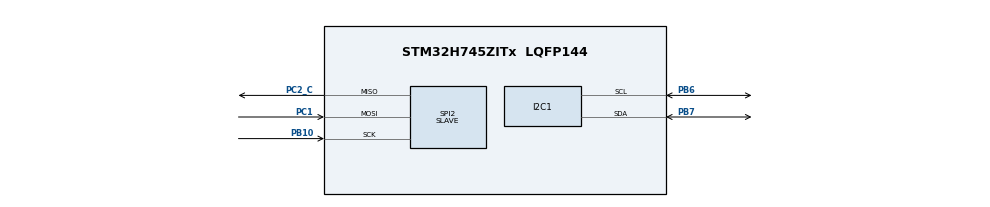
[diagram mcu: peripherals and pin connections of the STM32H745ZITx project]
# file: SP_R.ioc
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CortexM4.IPs=BDMA,CORTEX_M4\:I,DEBUG,DMA,FATFS_M4\:I,FREERTOS_M4\:I,GPIO,IWDG2\:I,MDMA,NVIC2\:I,OPENAMP_M4\:I,PDM2PCM_M4\:I,PWR,RCC,RESMGR_UTILITY,SYS_M4\:I,USB_DEVICE_M4\:I,USB_HOST_M4\:I,VREFBUF,WWDG2\:I
CortexM7.IPs=BDMA\:I,CORTEX_M7\:I,DEBUG\:I,DMA\:I,FATFS_M7\:I,FREERTOS_M7\:I,GPIO\:I,IWDG1\:I,MDMA\:I,NVIC1\:I,OPENAMP_M7\:I,PDM2PCM_M7\:I,PWR\:I,RCC\:I,RESMGR_UTILITY\:I,SYS\:I,USB_DEVICE_M7\:I,USB_HOST_M7\:I,VREFBUF\:I,WWDG1\:I,SPI2\:I,I2C1\:I
I2C1.Timing=0x10C0ECFF
Mcu.Family=STM32H7
Mcu.Name=STM32H745ZITx
Mcu.Package=LQFP144
NVIC1.I2C1_EV_IRQn=true\:0\:0\:false\:false\:true\:true\:true\:true
NVIC1.PriorityGroup=NVIC_PRIORITYGROUP_4
NVIC1.SPI2_IRQn=true\:0\:0\:false\:false\:true\:true\:true\:true
NVIC2.PriorityGroup=NVIC_PRIORITYGROUP_4
PB10.Mode=Full_Duplex_Slave
PB10.PinAttribute=CortexM7
PB10.Signal=SPI2_SCK
PB6.Mode=I2C
PB6.PinAttribute=CortexM7
PB6.Signal=I2C1_SCL
PB7.Mode=I2C
PB7.PinAttribute=CortexM7
PB7.Signal=I2C1_SDA
PC1.Mode=Full_Duplex_Slave
PC1.PinAttribute=CortexM7
PC1.Signal=SPI2_MOSI
PC2_C.Mode=Full_Duplex_Slave
PC2_C.PinAttribute=CortexM7
PC2_C.Signal=SPI2_MISO
ProjectManager.HeapSize=M4-0x200,M7-0x200
ProjectManager.StackSize=M4-0x400,M7-0x400
ProjectManager.TargetToolchain=STM32CubeIDE
RCC.ADCFreq_Value=129000000
RCC.APB1Freq_Value=100000000
RCC.APB2Freq_Value=100000000
RCC.APB3Freq_Value=100000000
RCC.APB4Freq_Value=100000000
RCC.CortexFreq_Value=100000000
RCC.DIVM1=4
RCC.DIVN1=12
RCC.HCLKFreq_Value=100000000
RCC.PLL2FRACN=0
RCC.PLL3FRACN=0
RCC.PLLFRACN=4096
RCC.SYSCLKFreq_VALUE=100000000
RCC.SYSCLKSource=RCC_SYSCLKSOURCE_PLLCLK
RCC.USBFreq_Value=100000000
SPI2.DataSize=SPI_DATASIZE_8BIT
SPI2.Direction=SPI_DIRECTION_2LINES
SPI2.Mode=SPI_MODE_SLAVE
SPI2.VirtualType=VM_SLAVE
board=custom

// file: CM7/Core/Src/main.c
/* USER CODE BEGIN Header */
/**
  ******************************************************************************
  * @file           : main.c
  * @brief          : Main program body
  ******************************************************************************
  * @attention
  *
  * Copyright (c) 2023 STMicroelectronics.
  * All rights reserved.
  *
  * This software is licensed under terms that can be found in the LICENSE file
  * in the root directory of this software component.
  * If no LICENSE file comes with this software, it is provided AS-IS.
  *
  ******************************************************************************
  */
/* USER CODE END Header */
#include "main.h"

/* USER CODE BEGIN PD */

#ifndef HSEM_ID_0
#define HSEM_ID_0 (0U) /* HW semaphore 0*/
#endif

/* USER CODE END PD */

I2C_HandleTypeDef hi2c1;

SPI_HandleTypeDef hspi2;

/* USER CODE BEGIN PV */
uint8_t receivedData;
/* USER CODE END PV */

void SystemClock_Config(void);
static void MX_GPIO_Init(void);
static void MX_SPI2_Init(void);
static void MX_I2C1_Init(void);

/* USER CODE BEGIN 0 */

void HAL_SPI_RxCpltCallback(SPI_HandleTypeDef *hspi)
{
    HAL_GPIO_WritePin(GPIOB, GPIO_PIN_0, GPIO_PIN_SET);
}
/* USER CODE END 0 */

int main(void)
{
/* USER CODE BEGIN Boot_Mode_Sequence_0 */
//  int32_t timeout;
/* USER CODE END Boot_Mode_Sequence_0 */

/* USER CODE BEGIN Boot_Mode_Sequence_1 */
  /* Wait until CPU2 boots and enters in stop mode or timeout*/
//  timeout = 0xFFFF;
//  while((__HAL_RCC_GET_FLAG(RCC_FLAG_D2CKRDY) != RESET) && (timeout-- > 0));
//  if ( timeout < 0 )
//  {
//  Error_Handler();
//  }
/* USER CODE END Boot_Mode_Sequence_1 */
  /* MCU Configuration--------------------------------------------------------*/

  /* Reset of all peripherals, Initializes the Flash interface and the Systick. */
  HAL_Init();

  /* USER CODE BEGIN Init */
  __HAL_RCC_GPIOB_CLK_ENABLE(); // Enable clock for GPIOF
  GPIO_InitTypeDef GPIOB_init = {};
  GPIOB_init.Pin = GPIO_PIN_0;
  GPIOB_init.Mode = GPIO_MODE_OUTPUT_PP;
  HAL_GPIO_Init(GPIOB, &GPIOB_init);
  /* USER CODE END Init */

  /* Configure the system clock */
  SystemClock_Config();
/* USER CODE BEGIN Boot_Mode_Sequence_2 */
/* When system initialization is finished, Cortex-M7 will release Cortex-M4 by means of
HSEM notification */
/*HW semaphore Clock enable*/
//__HAL_RCC_HSEM_CLK_ENABLE();
///*Take HSEM */
//HAL_HSEM_FastTake(HSEM_ID_0);
///*Release HSEM in order to notify the CPU2(CM4)*/
//HAL_HSEM_Release(HSEM_ID_0,0);
///* wait until CPU2 wakes up from stop mode */
//timeout = 0xFFFF;
//while((__HAL_RCC_GET_FLAG(RCC_FLAG_D2CKRDY) == RESET) && (timeout-- > 0));
//if ( timeout < 0 )
//{
//Error_Handler();
//}
/* USER CODE END Boot_Mode_Sequence_2 */

  /* Initialize all configured peripherals */
  MX_GPIO_Init();
  MX_SPI2_Init();
  MX_I2C1_Init();
  /* USER CODE BEGIN 2 */
  __HAL_RCC_SPI2_CLK_ENABLE();
//  NVIC_SetPriority(SPI2_IRQn, 0);
//
//  NVIC_EnableIRQ(SPI2_IRQn);
  hspi2.RxXferSize = 1;
  HAL_StatusTypeDef reception_stat;
  reception_stat = HAL_SPI_Receive_IT(&hspi2, &receivedData, 1);

  /* USER CODE END 2 */

  /* Infinite loop */
  while (1)
  {

  }
}

void SystemClock_Config(void)
{
  RCC_OscInitTypeDef RCC_OscInitStruct = {0};
  RCC_ClkInitTypeDef RCC_ClkInitStruct = {0};

  /** Supply configuration update enable
  */
  HAL_PWREx_ConfigSupply(PWR_DIRECT_SMPS_SUPPLY);

  /** Configure the main internal regulator output voltage
  */
  __HAL_PWR_VOLTAGESCALING_CONFIG(PWR_REGULATOR_VOLTAGE_SCALE3);

  while(!__HAL_PWR_GET_FLAG(PWR_FLAG_VOSRDY)) {}

  /** Initializes the RCC Oscillators according to the specified parameters
  * in the RCC_OscInitTypeDef structure.
  */
  RCC_OscInitStruct.OscillatorType = RCC_OSCILLATORTYPE_HSI;
  RCC_OscInitStruct.HSIState = RCC_HSI_DIV1;
  RCC_OscInitStruct.HSICalibrationValue = RCC_HSICALIBRATION_DEFAULT;
  RCC_OscInitStruct.PLL.PLLState = RCC_PLL_ON;
  RCC_OscInitStruct.PLL.PLLSource = RCC_PLLSOURCE_HSI;
  RCC_OscInitStruct.PLL.PLLM = 4;
  RCC_OscInitStruct.PLL.PLLN = 12;
  RCC_OscInitStruct.PLL.PLLP = 2;
  RCC_OscInitStruct.PLL.PLLQ = 2;
  RCC_OscInitStruct.PLL.PLLR = 2;
  RCC_OscInitStruct.PLL.PLLRGE = RCC_PLL1VCIRANGE_3;
  RCC_OscInitStruct.PLL.PLLVCOSEL = RCC_PLL1VCOWIDE;
  RCC_OscInitStruct.PLL.PLLFRACN = 4096;
  if (HAL_RCC_OscConfig(&RCC_OscInitStruct) != HAL_OK)
  {
    Error_Handler();
  }

  /** Initializes the CPU, AHB and APB buses clocks
  */
  RCC_ClkInitStruct.ClockType = RCC_CLOCKTYPE_HCLK|RCC_CLOCKTYPE_SYSCLK
                              |RCC_CLOCKTYPE_PCLK1|RCC_CLOCKTYPE_PCLK2
                              |RCC_CLOCKTYPE_D3PCLK1|RCC_CLOCKTYPE_D1PCLK1;
  RCC_ClkInitStruct.SYSCLKSource = RCC_SYSCLKSOURCE_PLLCLK;
  RCC_ClkInitStruct.SYSCLKDivider = RCC_SYSCLK_DIV1;
  RCC_ClkInitStruct.AHBCLKDivider = RCC_HCLK_DIV1;
  RCC_ClkInitStruct.APB3CLKDivider = RCC_APB3_DIV1;
  RCC_ClkInitStruct.APB1CLKDivider = RCC_APB1_DIV1;
  RCC_ClkInitStruct.APB2CLKDivider = RCC_APB2_DIV1;
  RCC_ClkInitStruct.APB4CLKDivider = RCC_APB4_DIV1;

  if (HAL_RCC_ClockConfig(&RCC_ClkInitStruct, FLASH_LATENCY_2) != HAL_OK)
  {
    Error_Handler();
  }
}

static void MX_I2C1_Init(void)
{

  hi2c1.Instance = I2C1;
  hi2c1.Init.Timing = 0x10C0ECFF;
  hi2c1.Init.OwnAddress1 = 0;
  hi2c1.Init.AddressingMode = I2C_ADDRESSINGMODE_7BIT;
  hi2c1.Init.DualAddressMode = I2C_DUALADDRESS_DISABLE;
  hi2c1.Init.OwnAddress2 = 0;
  hi2c1.Init.OwnAddress2Masks = I2C_OA2_NOMASK;
  hi2c1.Init.GeneralCallMode = I2C_GENERALCALL_DISABLE;
  hi2c1.Init.NoStretchMode = I2C_NOSTRETCH_DISABLE;
  if (HAL_I2C_Init(&hi2c1) != HAL_OK)
  {
    Error_Handler();
  }

  /** Configure Analogue filter
  */
  if (HAL_I2CEx_ConfigAnalogFilter(&hi2c1, I2C_ANALOGFILTER_ENABLE) != HAL_OK)
  {
    Error_Handler();
  }

  /** Configure Digital filter
  */
  if (HAL_I2CEx_ConfigDigitalFilter(&hi2c1, 0) != HAL_OK)
  {
    Error_Handler();
  }

}

static void MX_SPI2_Init(void)
{

  /* SPI2 parameter configuration*/
  hspi2.Instance = SPI2;
  hspi2.Init.Mode = SPI_MODE_SLAVE;
  hspi2.Init.Direction = SPI_DIRECTION_2LINES;
  hspi2.Init.DataSize = SPI_DATASIZE_8BIT;
  hspi2.Init.CLKPolarity = SPI_POLARITY_LOW;
  hspi2.Init.CLKPhase = SPI_PHASE_1EDGE;
  hspi2.Init.NSS = SPI_NSS_SOFT;
  hspi2.Init.FirstBit = SPI_FIRSTBIT_MSB;
  hspi2.Init.TIMode = SPI_TIMODE_DISABLE;
  hspi2.Init.CRCCalculation = SPI_CRCCALCULATION_DISABLE;
  hspi2.Init.CRCPolynomial = 0x0;
  hspi2.Init.NSSPMode = SPI_NSS_PULSE_DISABLE;
  hspi2.Init.NSSPolarity = SPI_NSS_POLARITY_LOW;
  hspi2.Init.FifoThreshold = SPI_FIFO_THRESHOLD_01DATA;
  hspi2.Init.TxCRCInitializationPattern = SPI_CRC_INITIALIZATION_ALL_ZERO_PATTERN;
  hspi2.Init.RxCRCInitializationPattern = SPI_CRC_INITIALIZATION_ALL_ZERO_PATTERN;
  hspi2.Init.MasterSSIdleness = SPI_MASTER_SS_IDLENESS_00CYCLE;
  hspi2.Init.MasterInterDataIdleness = SPI_MASTER_INTERDATA_IDLENESS_00CYCLE;
  hspi2.Init.MasterReceiverAutoSusp = SPI_MASTER_RX_AUTOSUSP_DISABLE;
  hspi2.Init.MasterKeepIOState = SPI_MASTER_KEEP_IO_STATE_DISABLE;
  hspi2.Init.IOSwap = SPI_IO_SWAP_DISABLE;
  if (HAL_SPI_Init(&hspi2) != HAL_OK)
  {
    Error_Handler();
  }

}

static void MX_GPIO_Init(void)
{

  /* GPIO Ports Clock Enable */
  __HAL_RCC_GPIOC_CLK_ENABLE();
  __HAL_RCC_GPIOB_CLK_ENABLE();

}

void Error_Handler(void)
{
  __disable_irq();
  while (1)
  {
  }
}
